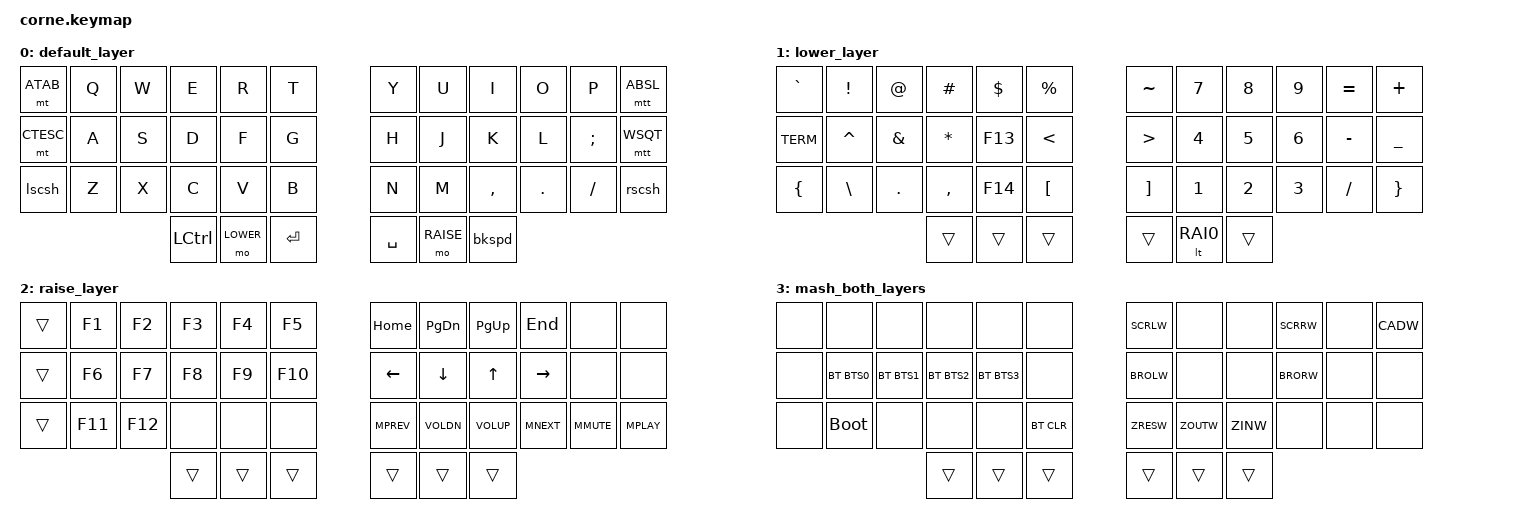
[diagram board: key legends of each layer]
#include <behaviors.dtsi>
#include <dt-bindings/zmk/keys.h>
#include <dt-bindings/zmk/bt.h>

// Layers
#define DEFAULT 0
#define LOWER 1
#define RAISE 2
#define MASH 3

// Aliases
#define ATAB  LALT TAB       // Mod-Tap shorthand for ALT when held, TAB when tapped
#define CTESC LCTRL ESC      // Mod-Tap shorthand for CTRL when held, ESC when tapped
#define RAI0  RAISE N0       // Mod-Tap shorthand for RAISE layer when held, or numpad 0 when typed
#define TERM  LG(ESC)        // Key-Press shorthand for CMD-ESC for summoning / toggling terminal
#define MPREV C_PREV         // Key-Press shorthand for PREV media key
#define MNEXT C_NEXT         // Key-Press shorthand for NEXT media key
#define VOLUP C_VOL_UP       // Key-Press shorthand for VOLUME UP media key
#define VOLDN C_VOL_DN       // Key-Press shorthand for VOLUME DOWN media key
#define MPLAY C_PP           // Key-Press shorthand for PLAY / PAUSE media key
#define MMUTE C_MUTE         // Key-Press shorthand for MUTE media key
#define BTS0  BT_SEL 0       // Select Bluetooth profile 0
#define BTS1  BT_SEL 1       // Select Bluetooth profile 1
#define BTS2  BT_SEL 2       // Select Bluetooth profile 2
#define BTS3  BT_SEL 3       // Select Bluetooth profile 3

// Windows Specific Aliases
#define ABSL  LALT BSLH      // Mod-Tap shorthand for ALT when held, BSLH when tapped
#define WSQT  LGUI SQT       // Mod-Tap shorthand for WIN when held, SQT when tapped
#define SCRLW LG(LC(LEFT))   // Key-Press shorthand for virtual desktop left in Windows
#define SCRRW LG(LC(RIGHT))  // Key-Press shorthand for virtual desktop right in Windows
#define BROLW LC(LS(TAB))    // Key-Press shorthand for browser tab left in Windows
#define BRORW LC(TAB)        // Key-Press shorthand for browser tab right in Windows
#define ZINW  LC(EQUAL)      // Key-Press shorthand for zoom in Windows
#define ZOUTW LC(MINUS)      // Key-Press shorthand for zoom out in Windows
#define ZRESW LC(N0)         // Key-Press shorthand for zoom reset in Windows
#define CADW  LC(LA(DEL))    // Key-Press shorthand for CTRL-ALT-DEL in Windows

/ {

    keymap {
        compatible = "zmk,keymap";

        default_layer {
            bindings = <
            // +----------+----------+----------+----------+----------+----------+     +----------+----------+----------+----------+--[ COMBO FOR DEL ]--+
            //   ALT TAB    Q          W          E          R          T                Y          U          I          O          P          ALT \ |
                 &mt ATAB   &kp Q      &kp W      &kp E      &kp R      &kp T            &kp Y      &kp U      &kp I      &kp O      &kp P      &mtt ABSL
            // +----------+----------+--[ HYPER + BIG HYPER COMBOS ]--+----------+     +----------+----------+----------+----------+----------+----------+
            //   CTRL ESC   A          S          D          F          G                H          J          K          L          ; :        WIN ' "
                 &mt CTESC  &kp A      &kp S      &kp D      &kp F      &kp G            &kp H      &kp J      &kp K      &kp L      &kp SEMI   &mtt WSQT
            // +----------+----------+----------+----------+----------+----------+     +----------+----------+----------+----------+----------+----------+
            //   SHIFT (    Z          X          C          V          B                N          M          , <        . >        / ?        SHIFT )
                 &lscsh     &kp Z      &kp X      &kp C      &kp V      &kp B            &kp N      &kp M      &kp COMMA  &kp DOT    &kp FSLH   &rscsh
            // +----------+----------+----------+----------+----------+----------+     +----------+----------+----------+----------+----------+----------+
            //                                    CTRL       LOWER      ENTER            SPACE      RAISE      BKSP DEL
                                                  &kp LCTRL  &mo LOWER  &kp ENTER        &kp SPACE  &mo RAISE  &bkspd
            //                                  +----------+----------+----------+     +----------+----------+----------+
            //
            // * Notes:
            //   - In standard CAPS key position, hold for CTRL, or tap for ESC
            //   - In standard TAB key position, hold for ALT, or tap for TAB
            //   - In standard SHIFT key positions, hold for SHIFT, or tap for open `(` and close `)` parentheses (left and right respectively)
            //   - In standard backslash position, hold for ALT, or tap for `\`
            //   - In standard quote position, hold for WIN, or tap for `'`
            //   - Combo D+F keys for HYPER (CTRL+ALT+CMD)
            //   - Combo S+D+F keys for BIG HYPER (SHIFT+CTRL+ALT+CMD)
            //   - Combo P+\ in top right corner for forward DEL
            //   - Shift backspace for forward delete
            //   - See other layers for more:
            //     - LOWER layer for symbols, numpad, summon apps function, summon terminal function, run macros function, etc.
            //     - RAISE layer for hjkl arrows, page navigation keys, media keys, function keys, spotlight search, etc.
            //     - MASH layer (LOWER+RAISE) for default layer toggling, screen switching, browser tab switching, zoom helpers, etc.
            >;
        };

        lower_layer {
            bindings = <
            // +----------+----------+----------+----------+----------+----------+     +----------+----------+----------+----------+----------+----------+
            //   `          !          @          #          $          %                ~          7          8          9          =          +
                 &kp GRAVE  &kp EXCL   &kp AT     &kp HASH   &kp DLLR   &kp PRCNT        &kp TILDE  &kp N7     &kp N8     &kp N9     &kp EQUAL  &kp PLUS
            // +----------+----------+----------+----------+----------+----------+     +----------+----------+----------+----------+----------+----------+
            //   OPEN TERM  ^          &          *          OPEN APP   <                >          4          5          6          -          _
                 &kp TERM   &kp CARET  &kp AMPS   &kp ASTRK  &kp F13    &kp LT           &kp GT     &kp N4     &kp N5     &kp N6     &kp MINUS  &kp UNDER
            // +----------+----------+----------+----------+----------+----------+     +----------+----------+----------+----------+----------+----------+
            //   {          \          .          ,          RUN MACRO  [                ]          1          2          3          /          }
                 &kp LBRC   &kp BSLH   &kp DOT    &kp COMMA  &kp F14    &kp LBKT         &kp RBKT   &kp N1     &kp N2     &kp N3     &kp FSLH   &kp RBRC
            // +----------+----------+----------+----------+----------+----------+     +----------+----------+----------+----------+----------+----------+
            //                                                                                      0 RAISE
                                                  &trans     &trans     &trans           &trans     &lt RAI0   &trans
            //                                  +----------+----------+----------+     +----------+----------+----------+
            //
            // * Notes:
            //   - Almost all symbols accessible on this layer
            //   - Numpad under right hand
            //   - Summon terminal in standard CAPS position (which posts CMD+ESC for handling in OS)
            //   - Summon apps modal in `F` position (for 'find' or open app, which posts F13 for handling in OS)
            //   - Run macro modal in `V` position (which posts F14 for handling in OS)
            //     - The above three mentioned functions can be configured via Hammerspoon, Autohotkey, etc.
            >;
        };

        raise_layer {
            bindings = <
            // +----------+----------+----------+----------+----------+----------+     +----------+----------+----------+----------+----------+----------+
            //              FUNCTION KEYS 1-5                                            PAGE NAVIGATION
                 &trans     &kp F1     &kp F2     &kp F3     &kp F4     &kp F5           &kp HOME   &kp PG_DN  &kp PG_UP  &kp END    &none      &none
            // +----------+----------+----------+----------+----------+----------+     +----------+----------+----------+----------+----------+----------+
            //              FUNCTION KEYS 6-10                                           HJKL ARROW KEYS
                 &trans     &kp F6     &kp F7     &kp F8     &kp F9     &kp F10          &kp LEFT   &kp DOWN   &kp UP     &kp RIGHT  &none      &none
            // +----------+----------+----------+----------+----------+----------+     +----------+----------+----------+----------+----------+----------+
            //              FUNCTION KEYS 11-12                                          MEDIA KEYS
                 &trans     &kp F11    &kp F12    &none      &none      &none            &kp MPREV  &kp VOLDN  &kp VOLUP  &kp MNEXT  &kp MMUTE  &kp MPLAY
            // +----------+----------+----------+----------+----------+----------+     +----------+----------+----------+----------+----------+----------+
            //
                                                  &trans     &trans     &trans           &trans     &trans     &trans
            //                                  +----------+----------+----------+     +----------+----------+----------+
            //
            // * Notes:
            //   - Arrow keys in HJKL position
            //   - Page navigation (HOME, PG DOWN, PG UP, END) in HJKL-like position, but up one row
            //   - Media keys (PREV, VOL DOWN, VOL UP, NEXT, etc.) in HJKL-like position, but down one row
            //     - These are intentionally on raise layer so that you can play/pause/mute with one hand while on phone, etc.
            //   - Function keys on left split
            >;
        };

        mash_both_layers {
            bindings = <
            // +----------+----------+----------+----------+----------+----------+     +----------+----------+----------+----------+----------+----------+
            //                                                                           SCREEN SWITCHING                                   CTRL+ALT+DEL
                 &none     &none       &none      &none      &none      &none            &kp SCRLW  &none      &none      &kp SCRRW  &none      &kp CADW
            // +----------+----------+----------+----------+----------+----------+     +----------+----------+----------+----------+----------+----------+
            //             BLUETOOTH PROFILES                                            BROWSER TAB SWITCHING
                 &none     &bt BTS0    &bt BTS1   &bt BTS2   &bt BTS3   &none            &kp BROLW  &none      &none      &kp BRORW  &none      &none
            // +----------+----------+----------+----------+----------+----------+     +----------+----------+----------+----------+----------+----------+
            //             ZMK FLASH                              BLUETOOTH CLEAR        ZOOM IN, OUT, AND RESET
                 &none     &bootloader &none      &none      &none     &bt BT_CLR        &kp ZRESW  &kp ZOUTW  &kp ZINW   &none      &none      &none
            // +----------+----------+----------+----------+----------+----------+     +----------+----------+----------+----------+----------+----------+
            //
                                                  &trans     &trans     &trans           &trans     &trans     &trans
            //                                  +----------+----------+----------+     +----------+----------+----------+
            //
            // * Notes:
            //   - Many call this the ADJUST layer, but we're calling it MASH because you mash both LOWER + RAISE keys
            //   - Hit `Z` position to put central half into ZMK bootloader mode for flashing keymap (can also double press physical reset switch)
            //   - HJKL-like screen switching, browser tab switching, and zoom in/out/reset helpers on right split
            //   - Hit top right key to CTRL+ALT+DELETE
            >;
        };

    };

    conditional_layers {
        compatible = "zmk,conditional-layers";
        mash_both_layers {
            if-layers = <LOWER RAISE>;
            then-layer = <MASH>;
        };
    };

    behaviors {
        mtt: mod_tap_with_tap_preferred {
            compatible = "zmk,behavior-hold-tap";
            #binding-cells = <2>;
            tapping-term-ms = <200>;
            flavor = "tap-preferred";
            bindings = <&kp>, <&kp>;
        };

        lscsh: left_space_cadet_shift {
            compatible = "zmk,behavior-mod-morph";
            #binding-cells = <0>;
            bindings = <&mt LSHFT LPAR>, <&close_and_open_parens>;
            mods = <(MOD_RSFT)>;
        };

        rscsh: right_space_cadet_shift {
            compatible = "zmk,behavior-mod-morph";
            #binding-cells = <0>;
            bindings = <&mt RSHFT RPAR>, <&open_and_close_parens>;
            mods = <(MOD_LSFT)>;
        };

        bkspd: backspace_or_shift_delete {
            compatible = "zmk,behavior-mod-morph";
            #binding-cells = <0>;
            bindings = <&kp BACKSPACE>, <&kp DELETE>;
            mods = <(MOD_LSFT)>;
        };
    };

    macros {
        open_and_close_parens: open_and_close_parens {
            compatible = "zmk,behavior-macro";
            #binding-cells = <0>;
            bindings = <&macro_tap &kp LPAR &kp RPAR>;
        };

        close_and_open_parens: close_and_open_parens {
            compatible = "zmk,behavior-macro";
            #binding-cells = <0>;
            bindings = <&macro_tap &kp RPAR &kp LPAR>;
        };
    };

    combos {
        compatible = "zmk,combos";
        combo_hyper {
            timeout-ms = <50>;
            key-positions = <15 16>;
            bindings = <&kp LG(LA(LCTRL))>;
        };
        combo_big_hyper {
            timeout-ms = <50>;
            key-positions = <14 15 16>;
            bindings = <&kp LS(LG(LA(LCTRL)))>;
        };
        combo_del_in_top_right_corner {
            timeout-ms = <50>;
            key-positions = <10 11>;
            bindings = <&kp DEL>;
        };
    };
};
